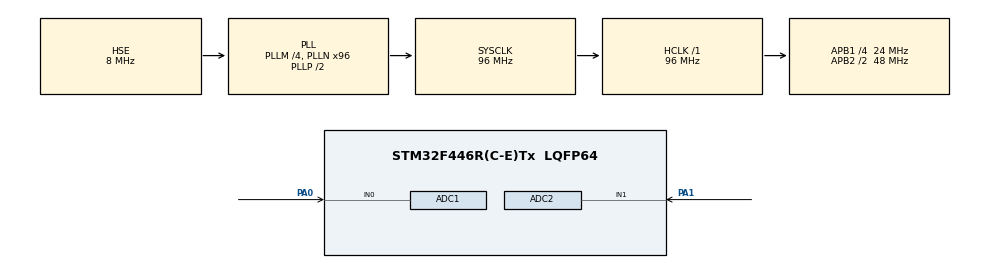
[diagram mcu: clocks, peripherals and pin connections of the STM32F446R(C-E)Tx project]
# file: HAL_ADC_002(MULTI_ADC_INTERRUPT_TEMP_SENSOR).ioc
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ADC1.Channel-0\#ChannelRegularConversion=ADC_CHANNEL_VREFINT
ADC1.Channel-1\#ChannelRegularConversion=ADC_CHANNEL_TEMPSENSOR
ADC1.Channel-2\#ChannelRegularConversion=ADC_CHANNEL_0
ADC1.ContinuousConvMode=ENABLE
ADC1.NbrOfConversion=3
ADC1.NbrOfConversionFlag=1
ADC1.Rank-0\#ChannelRegularConversion=1
ADC1.Rank-1\#ChannelRegularConversion=2
ADC1.Rank-2\#ChannelRegularConversion=3
ADC1.SamplingTime-0\#ChannelRegularConversion=ADC_SAMPLETIME_144CYCLES
ADC1.SamplingTime-1\#ChannelRegularConversion=ADC_SAMPLETIME_144CYCLES
ADC1.SamplingTime-2\#ChannelRegularConversion=ADC_SAMPLETIME_144CYCLES
ADC1.ScanConvMode=ENABLE
ADC1.master=1
ADC2.Channel-2\#ChannelRegularConversion=ADC_CHANNEL_1
ADC2.ContinuousConvMode=ENABLE
ADC2.NbrOfConversion=1
ADC2.NbrOfConversionFlag=1
ADC2.Rank-2\#ChannelRegularConversion=1
ADC2.SamplingTime-2\#ChannelRegularConversion=ADC_SAMPLETIME_144CYCLES
ADC2.ScanConvMode=DISABLE
Mcu.Family=STM32F4
Mcu.Name=STM32F446R(C-E)Tx
Mcu.Package=LQFP64
NVIC.ADC_IRQn=true\:0\:0\:false\:false\:true\:true\:true
NVIC.PriorityGroup=NVIC_PRIORITYGROUP_4
PA0-WKUP.Signal=ADCx_IN0
PA1.Signal=ADCx_IN1
PH0-OSC_IN.Mode=HSE-External-Oscillator
PH0-OSC_IN.Signal=RCC_OSC_IN
PH1-OSC_OUT.Mode=HSE-External-Oscillator
PH1-OSC_OUT.Signal=RCC_OSC_OUT
ProjectManager.HeapSize=0x200
ProjectManager.StackSize=0x400
ProjectManager.TargetToolchain=MDK-ARM V5
RCC.AHBFreq_Value=96000000
RCC.APB1CLKDivider=RCC_HCLK_DIV4
RCC.APB1Freq_Value=24000000
RCC.APB1TimFreq_Value=48000000
RCC.APB2CLKDivider=RCC_HCLK_DIV2
RCC.APB2Freq_Value=48000000
RCC.APB2TimFreq_Value=96000000
RCC.CortexFreq_Value=96000000
RCC.HCLKFreq_Value=96000000
RCC.HSE_VALUE=8000000
RCC.PLLM=4
RCC.PLLN=96
RCC.PLLSourceVirtual=RCC_PLLSOURCE_HSE
RCC.SYSCLKFreq_VALUE=96000000
RCC.SYSCLKSource=RCC_SYSCLKSOURCE_PLLCLK
RCC.USBFreq_Value=96000000
RCC.VCOOutputFreq_Value=192000000
SH.ADCx_IN0.0=ADC1_IN0,IN0
SH.ADCx_IN1.0=ADC2_IN1,IN1
VP_ADC1_TempSens_Input.Mode=IN-TempSens
VP_ADC1_Vref_Input.Mode=IN-Vrefint
board=custom

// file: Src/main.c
/* USER CODE BEGIN Header */
/**
  ******************************************************************************
  * @file           : main.c
  * @brief          : Main program body
  ******************************************************************************
  * @attention
  *
  * <h2><center>&copy; Copyright (c) 2020 STMicroelectronics.
  * All rights reserved.</center></h2>
  *
  * This software component is licensed by ST under BSD 3-Clause license,
  * the "License"; You may not use this file except in compliance with the
  * License. You may obtain a copy of the License at:
  *                        opensource.org/licenses/BSD-3-Clause
  *
  ******************************************************************************
  */
/* USER CODE END Header */

#include "main.h"

/* USER CODE BEGIN PD */
	#define 	VREFIN_CAL	((uint16_t*)	((uint32_t)	0x1FFF7A2A))		// 	VDD degerini bulmak için gerekli olan register
	#define		V25					(float)										0.76						// 	Sicaklik sensoru icin gerekli datashette mevcut
	#define		avg_slope		(float)										2.5/1000				//	Sicaklik sensoru icin gerekli datashette mevcut
/* USER CODE END PD */

ADC_HandleTypeDef hadc1;
ADC_HandleTypeDef hadc2;

/* USER CODE BEGIN PV */
	uint16_t		adc1_data[3],adc2_data=0;

	unsigned	char count=0;

	float				Vadc1_ch0=0,	Vadc2_ch1=0,	Vref=0,		Vsense=0,		temperature=0;
/* USER CODE END PV */

void SystemClock_Config(void);
static void MX_GPIO_Init(void);
static void MX_ADC1_Init(void);
static void MX_ADC2_Init(void);
/* USER CODE BEGIN PFP */
void	HAL_ADC_ConvCpltCallback(ADC_HandleTypeDef* hadc)
{
	if(__HAL_ADC_GET_FLAG(&hadc1,ADC_FLAG_EOC)!=RESET)		//	1. pot interrupt func
	{
		adc1_data[count]	=	HAL_ADC_GetValue(&hadc1);

		count++;

		if(count	==	3)
				count	=	0;

		/*	VDDA	=	3.3	*	(VREFIN_CAL	/	VREFIN_DATA)	// VREFIN_CAL:datasheetteki registerin adresinde okudugumuz deger		VREFIN_DATA: Vrefint kanalindan okudugumuz deger

				VADC	=	VDDA	*	(	ADC_DATA	/	2^n-1	)			// n:resoulation rate		ADC_DATA:adc kanalindan okudugumuz veri
		*/

		Vref			=	(float)	3.3*	(*VREFIN_CAL)/adc1_data[0];

		Vsense		=		Vref	*	adc1_data[1]	;

		/*	Temperature (in °C) = {(VSENSE – V25) / Avg_Slope} + 25		*/	// Formula

		temperature	=	((Vsense -	V25)	/	avg_slope)	+	25	;

		Vadc1_ch0	=		Vref	*	adc1_data[2]	/	4095	;

	}
	if(__HAL_ADC_GET_FLAG(&hadc2,ADC_FLAG_EOC)!=RESET)		//	2. pot interrupt funct
	{
		adc2_data=		HAL_ADC_GetValue(&hadc2)	;
		Vadc2_ch1	=		Vref	*	adc2_data	/	4095	;

	}

}
/* USER CODE END PFP */

int main(void)
{

  /* MCU Configuration--------------------------------------------------------*/

  /* Reset of all peripherals, Initializes the Flash interface and the Systick. */
  HAL_Init();

  /* Configure the system clock */
  SystemClock_Config();

  /* Initialize all configured peripherals */
  MX_GPIO_Init();
  MX_ADC1_Init();
  MX_ADC2_Init();
  /* USER CODE BEGIN 2 */

	HAL_ADC_Start_IT(&hadc1);
	HAL_ADC_Start_IT(&hadc2);
  /* USER CODE END 2 */

  /* Infinite loop */
  while (1)
  {

  }
}

void SystemClock_Config(void)
{
  RCC_OscInitTypeDef RCC_OscInitStruct = {0};
  RCC_ClkInitTypeDef RCC_ClkInitStruct = {0};

  /** Configure the main internal regulator output voltage
  */
  __HAL_RCC_PWR_CLK_ENABLE();
  __HAL_PWR_VOLTAGESCALING_CONFIG(PWR_REGULATOR_VOLTAGE_SCALE3);
  /** Initializes the CPU, AHB and APB busses clocks
  */
  RCC_OscInitStruct.OscillatorType = RCC_OSCILLATORTYPE_HSE;
  RCC_OscInitStruct.HSEState = RCC_HSE_ON;
  RCC_OscInitStruct.PLL.PLLState = RCC_PLL_ON;
  RCC_OscInitStruct.PLL.PLLSource = RCC_PLLSOURCE_HSE;
  RCC_OscInitStruct.PLL.PLLM = 4;
  RCC_OscInitStruct.PLL.PLLN = 96;
  RCC_OscInitStruct.PLL.PLLP = RCC_PLLP_DIV2;
  RCC_OscInitStruct.PLL.PLLQ = 2;
  RCC_OscInitStruct.PLL.PLLR = 2;
  if (HAL_RCC_OscConfig(&RCC_OscInitStruct) != HAL_OK)
  {
    Error_Handler();
  }
  /** Initializes the CPU, AHB and APB busses clocks
  */
  RCC_ClkInitStruct.ClockType = RCC_CLOCKTYPE_HCLK|RCC_CLOCKTYPE_SYSCLK
                              |RCC_CLOCKTYPE_PCLK1|RCC_CLOCKTYPE_PCLK2;
  RCC_ClkInitStruct.SYSCLKSource = RCC_SYSCLKSOURCE_PLLCLK;
  RCC_ClkInitStruct.AHBCLKDivider = RCC_SYSCLK_DIV1;
  RCC_ClkInitStruct.APB1CLKDivider = RCC_HCLK_DIV4;
  RCC_ClkInitStruct.APB2CLKDivider = RCC_HCLK_DIV2;

  if (HAL_RCC_ClockConfig(&RCC_ClkInitStruct, FLASH_LATENCY_3) != HAL_OK)
  {
    Error_Handler();
  }
}

static void MX_ADC1_Init(void)
{

  ADC_ChannelConfTypeDef sConfig = {0};

  /** Configure the global features of the ADC (Clock, Resolution, Data Alignment and number of conversion)
  */
  hadc1.Instance = ADC1;
  hadc1.Init.ClockPrescaler = ADC_CLOCK_SYNC_PCLK_DIV2;
  hadc1.Init.Resolution = ADC_RESOLUTION_12B;
  hadc1.Init.ScanConvMode = ENABLE;
  hadc1.Init.ContinuousConvMode = ENABLE;
  hadc1.Init.DiscontinuousConvMode = DISABLE;
  hadc1.Init.ExternalTrigConvEdge = ADC_EXTERNALTRIGCONVEDGE_NONE;
  hadc1.Init.ExternalTrigConv = ADC_SOFTWARE_START;
  hadc1.Init.DataAlign = ADC_DATAALIGN_RIGHT;
  hadc1.Init.NbrOfConversion = 3;
  hadc1.Init.DMAContinuousRequests = DISABLE;
  hadc1.Init.EOCSelection = ADC_EOC_SINGLE_CONV;
  if (HAL_ADC_Init(&hadc1) != HAL_OK)
  {
    Error_Handler();
  }
  /** Configure for the selected ADC regular channel its corresponding rank in the sequencer and its sample time.
  */
  sConfig.Channel = ADC_CHANNEL_VREFINT;
  sConfig.Rank = 1;
  sConfig.SamplingTime = ADC_SAMPLETIME_144CYCLES;
  if (HAL_ADC_ConfigChannel(&hadc1, &sConfig) != HAL_OK)
  {
    Error_Handler();
  }
  /** Configure for the selected ADC regular channel its corresponding rank in the sequencer and its sample time.
  */
  sConfig.Channel = ADC_CHANNEL_TEMPSENSOR;
  sConfig.Rank = 2;
  if (HAL_ADC_ConfigChannel(&hadc1, &sConfig) != HAL_OK)
  {
    Error_Handler();
  }
  /** Configure for the selected ADC regular channel its corresponding rank in the sequencer and its sample time.
  */
  sConfig.Channel = ADC_CHANNEL_0;
  sConfig.Rank = 3;
  if (HAL_ADC_ConfigChannel(&hadc1, &sConfig) != HAL_OK)
  {
    Error_Handler();
  }

}

static void MX_ADC2_Init(void)
{

  ADC_ChannelConfTypeDef sConfig = {0};

  /** Configure the global features of the ADC (Clock, Resolution, Data Alignment and number of conversion)
  */
  hadc2.Instance = ADC2;
  hadc2.Init.ClockPrescaler = ADC_CLOCK_SYNC_PCLK_DIV2;
  hadc2.Init.Resolution = ADC_RESOLUTION_12B;
  hadc2.Init.ScanConvMode = DISABLE;
  hadc2.Init.ContinuousConvMode = ENABLE;
  hadc2.Init.DiscontinuousConvMode = DISABLE;
  hadc2.Init.ExternalTrigConvEdge = ADC_EXTERNALTRIGCONVEDGE_NONE;
  hadc2.Init.ExternalTrigConv = ADC_SOFTWARE_START;
  hadc2.Init.DataAlign = ADC_DATAALIGN_RIGHT;
  hadc2.Init.NbrOfConversion = 1;
  hadc2.Init.DMAContinuousRequests = DISABLE;
  hadc2.Init.EOCSelection = ADC_EOC_SINGLE_CONV;
  if (HAL_ADC_Init(&hadc2) != HAL_OK)
  {
    Error_Handler();
  }
  /** Configure for the selected ADC regular channel its corresponding rank in the sequencer and its sample time.
  */
  sConfig.Channel = ADC_CHANNEL_1;
  sConfig.Rank = 1;
  sConfig.SamplingTime = ADC_SAMPLETIME_144CYCLES;
  if (HAL_ADC_ConfigChannel(&hadc2, &sConfig) != HAL_OK)
  {
    Error_Handler();
  }

}

static void MX_GPIO_Init(void)
{

  /* GPIO Ports Clock Enable */
  __HAL_RCC_GPIOH_CLK_ENABLE();
  __HAL_RCC_GPIOA_CLK_ENABLE();

}

void Error_Handler(void)
{
}

/************************ (C) COPYRIGHT STMicroelectronics *****END OF FILE****/
